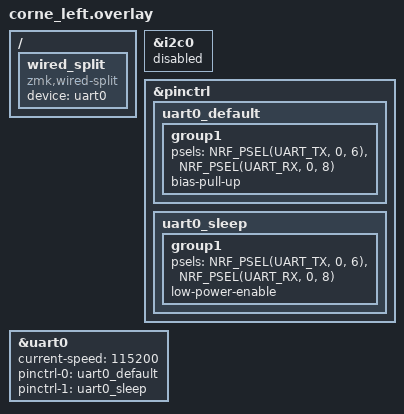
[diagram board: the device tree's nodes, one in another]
/*
 * Wired split UART overlay for left (central) half.
 * Unidirectional: RX on P0.08 (TRRS data) receives from peripheral.
 * TX on P0.06 (dummy, not connected to TRRS).
 */

#include <dt-bindings/pinctrl/nrf-pinctrl.h>

/* Disable I2C — uart0 shares the same nRF SERIAL0 peripheral */
&i2c0 {
    status = "disabled";
};

&pinctrl {
    uart0_default: uart0_default {
        /* Delete stale group2 (TX on P0.06) inherited from nice_nano-pinctrl.dtsi */
        /delete-node/ group2;
        group1 {
            psels = <NRF_PSEL(UART_TX, 0, 6)>,
                    <NRF_PSEL(UART_RX, 0, 8)>;
            bias-pull-up;
        };
    };
    uart0_sleep: uart0_sleep {
        group1 {
            psels = <NRF_PSEL(UART_TX, 0, 6)>,
                    <NRF_PSEL(UART_RX, 0, 8)>;
            low-power-enable;
        };
    };
};

&uart0 {
    status = "okay";
    current-speed = <115200>;
    pinctrl-0 = <&uart0_default>;
    pinctrl-1 = <&uart0_sleep>;
    pinctrl-names = "default", "sleep";
};

/ {
    wired_split {
        compatible = "zmk,wired-split";
        device = <&uart0>;
    };
};
